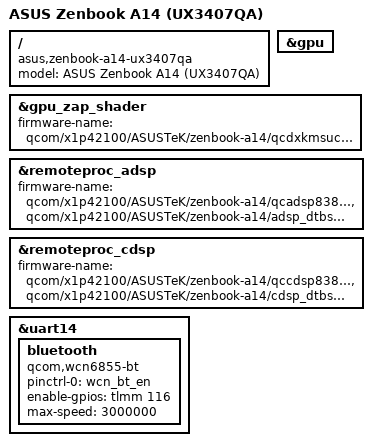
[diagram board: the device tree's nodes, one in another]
// SPDX-License-Identifier: BSD-3-Clause
/*
 * Copyright (c) 2025 Qualcomm Innovation Center, Inc. All rights reserved.
 * Copyright (c) 2025 Aleksandrs Vinarskis <alex.vinarskis@gmail.com>
 */

/dts-v1/;

#include "x1p42100.dtsi"
#include "x1-zenbook-a14.dtsi"

/delete-node/ &pmc8380_6;
/delete-node/ &pmc8380_6_thermal;

/ {
	model = "ASUS Zenbook A14 (UX3407QA)";
	compatible = "asus,zenbook-a14-ux3407qa", "qcom,x1p42100";
};

&gpu {
	status = "okay";
};

&gpu_zap_shader {
	firmware-name = "qcom/x1p42100/ASUSTeK/zenbook-a14/qcdxkmsucpurwa.mbn";
};

&remoteproc_adsp {
	firmware-name = "qcom/x1p42100/ASUSTeK/zenbook-a14/qcadsp8380.mbn",
			"qcom/x1p42100/ASUSTeK/zenbook-a14/adsp_dtbs.elf";

	status = "okay";
};

&remoteproc_cdsp {
	firmware-name = "qcom/x1p42100/ASUSTeK/zenbook-a14/qccdsp8380.mbn",
			"qcom/x1p42100/ASUSTeK/zenbook-a14/cdsp_dtbs.elf";

	status = "okay";
};

&uart14 {
	status = "okay";

	bluetooth {
		compatible = "qcom,wcn6855-bt";
		pinctrl-names = "default";
		pinctrl-0 = <&wcn_bt_en>;
		enable-gpios = <&tlmm 116 GPIO_ACTIVE_HIGH>;
		max-speed = <3000000>;
	};
};
